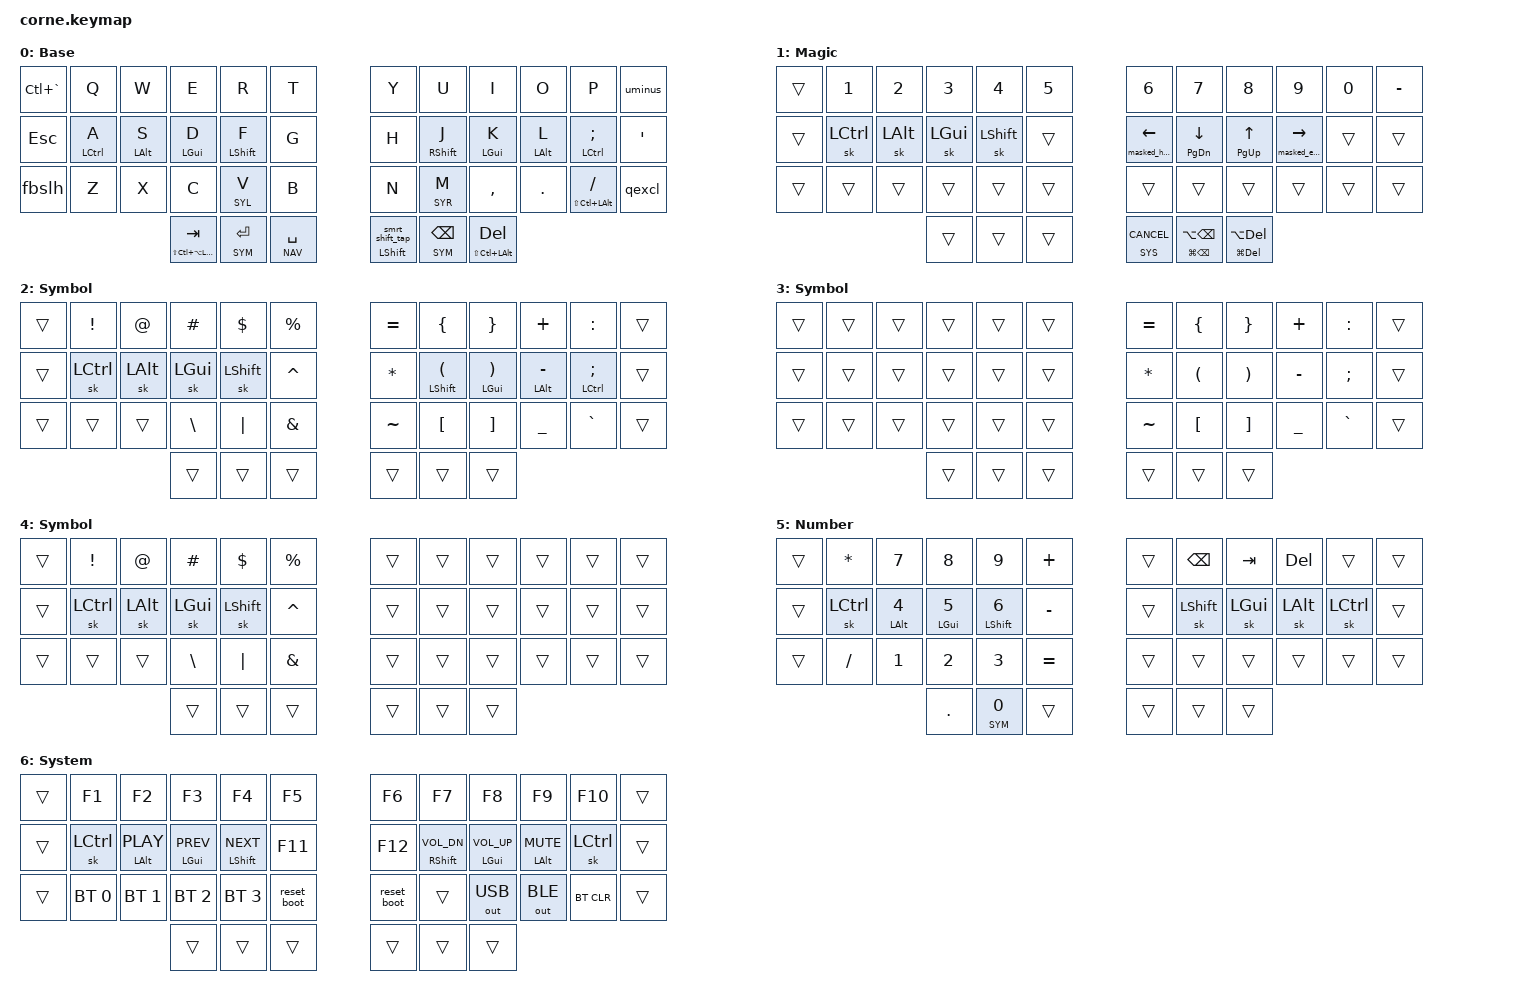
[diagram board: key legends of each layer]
#include <behaviors.dtsi>
#include <dt-bindings/zmk/keys.h>
#include <dt-bindings/zmk/bt.h>
#include <dt-bindings/zmk/outputs.h>
#include <dt-bindings/zmk/pointing.h>

#define DEF 0
#define NAV 1
#define SYM 2
#define SYL 3
#define SYR 4
#define NUM 5
#define SYS 6

#define XXX &none
#define ___ &trans

/* Global defaults */

#define QUICK_TAP_MS 175

&sk {
  release-after-ms = <900>;
  quick-release;
};

&sl { // Allow sticky mods to chord across sticky layers.
  ignore-modifiers;
};

&lt {
  flavor = "balanced";
  tapping-term-ms = <200>;
  quick-tap-ms = <QUICK_TAP_MS>;
};

/* Homerow mods */

#define KEYS_L 5 4 3 2 1 0 17 16 15 14 13 12 29 28 27 26 25 24
// #define KEYS_L 0 1 2 3 4 10 11 12 13 14 20 21 22 23 24
#define KEYS_R 6 7 8 9 10 11 18 19 20 21 22 23 30 31 32 33 34 35
// #define KEYS_R 5 6 7 8 9 15 16 17 18 19 25 26 27 28 29
#define THUMBS 36 37 38 39 40 41
// #define THUMBS 30 31 32 33

/* Nav cluster */

&mt { // Trigger tap-action on all interrupts.
  flavor = "tap-preferred";
  tapping-term-ms = <220>;
  quick-tap-ms = <220>;
  hold-trigger-key-positions = <0>;
};

// Home-row mods
#define HRLPAR  &hmr LSHFT LPAR
#define HRRPAR  &hmr LGUI  RPAR
#define HRMINUS &hmr LALT  MINUS
#define HRSEMI  &hmr LCTRL SEMI

#define HRPLAY &hml LALT  C_PLAY
#define HRPREV &hml LGUI  C_PREV
#define HRNEXT &hml LSHFT C_NEXT
#define HRVOLD &hml RSHFT C_VOL_DN
#define HRVOLU &hml LGUI  C_VOL_UP
#define HRMUTE &hml LALT  C_MUTE

#define HYP_TAB &mt LS(LC(LA(LGUI))) TAB
#define MEH_DEL &mt LS(LC(LALT))     DEL

#define MEH_SLH   &mt LS(LC(LALT)) FSLH
#define NAV_LEFT  &mt_home 0   LEFT     // Tap: left         | Long-tap: start of line.
#define NAV_DOWN  &mt PG_DN    DOWN     // Tap: down         | Long-tap: page down.
#define NAV_UP    &mt PG_UP    UP       // Tap: up           | Long-tap: page up.
#define NAV_RIGHT &mt_end 0    RIGHT    // Tap: right        | Long-tap: end   of line.
#define NAV_BSPC  &mt LG(BSPC) LA(BSPC) // Tap: bspc word    | Long-tap: bspc line.
#define NAV_DEL   &mt LG(DEL)  LA(DEL)  // Tap: del  word    | Long-tap: del  line.

/* Magic-shift & auto-layers */
#define SMRT_SHIFT &smrt_shift LSHFT 0

// Misc aliases. [TODO: clean up]
#define SYS_CANCEL &lt SYS K_CANCEL      // Cancel caps-word & auto-layers.
#define TERMNL     &kp LC(GRAVE)         // Open Terminal in VSCode
#define DSK_PREV   &kp LC(LEFT)          // Prev desktop.
#define DSK_APP    &kp LC(DOWN)          // Application windows.
#define DSK_ALL    &kp LC(UP)            // Mission Control.
#define DSK_NEXT   &kp LC(RIGHT)         // Next desktop.

/ {
  behaviors {
    hml: hml {
      compatible = "zmk,behavior-hold-tap";
      #binding-cells = <2>;
      bindings = <&kp>, <&kp>;
      flavor = "balanced";
      tapping-term-ms = <280>;
      quick-tap-ms = <QUICK_TAP_MS>;
      require-prior-idle-ms = <120>;
      hold-trigger-on-release;
      hold-trigger-key-positions = <KEYS_R THUMBS>;
    };
    hmr: hmr {
      compatible = "zmk,behavior-hold-tap";
      #binding-cells = <2>;
      bindings = <&kp>, <&kp>;
      flavor = "balanced";
      tapping-term-ms = <280>;
      quick-tap-ms = <QUICK_TAP_MS>;
      require-prior-idle-ms = <120>;
      hold-trigger-on-release;
      hold-trigger-key-positions = <KEYS_L THUMBS>;
    };
    bml: bml {
      compatible = "zmk,behavior-hold-tap";
      #binding-cells = <2>;
      bindings = <&mo>, <&kp>;
      flavor = "balanced";
      tapping-term-ms = <200>;
      quick-tap-ms = <QUICK_TAP_MS>;
      require-prior-idle-ms = <120>;
      hold-trigger-on-release;
      hold-trigger-key-positions = <KEYS_R THUMBS>;
    };
    bmr: bmr {
      compatible = "zmk,behavior-hold-tap";
      #binding-cells = <2>;
      bindings = <&mo>, <&kp>;
      flavor = "balanced";
      tapping-term-ms = <200>;
      quick-tap-ms = <QUICK_TAP_MS>;
      require-prior-idle-ms = <120>;
      hold-trigger-on-release;
      hold-trigger-key-positions = <KEYS_L THUMBS>;
    };

    mt_home: mt_home {
      compatible = "zmk,behavior-hold-tap";
      #binding-cells = <2>;
      bindings = <&masked_home>, <&kp>;
      flavor = "tap-preferred";
      tapping-term-ms = <220>;
      quick-tap-ms = <220>;
      hold-trigger-key-positions = <0>;
    };
    mt_end: mt_end {
      compatible = "zmk,behavior-hold-tap";
      #binding-cells = <2>;
      bindings = <&masked_end>, <&kp>;
      flavor = "tap-preferred";
      tapping-term-ms = <220>;
      quick-tap-ms = <220>;
      hold-trigger-key-positions = <0>;
    };

    // Tap: sticky-shift
    // Shift + tap/ double-tap: caps-word | Hold: shift.
    smrt_shift: smrt_shift {
      compatible = "zmk,behavior-hold-tap";
      #binding-cells = <2>;
      bindings = <&kp>, <&smrt_shift_tap>;
      flavor = "balanced";
      tapping-term-ms = <200>;
      quick-tap-ms = <QUICK_TAP_MS>;
    };
    smrt_shift_tap: smrt_shift_tap {
      compatible = "zmk,behavior-mod-morph";
      #binding-cells = <0>;
      bindings = <&sk LSHFT>, <&caps_word>;
      mods = <(MOD_LSFT)>;
    };

    // Mask GUI on left/right hold to avoid accidental jumps to start/end of doc.
    masked_home: masked_home {
      compatible = "zmk,behavior-mod-morph";
      #binding-cells = <0>;
      bindings = <&kp LG(LEFT)>, <&kp LG(LEFT)>;
      mods = <(MOD_LGUI)>;
    };
    masked_end: masked_end {
      compatible = "zmk,behavior-mod-morph";
      #binding-cells = <0>;
      bindings = <&kp LG(RIGHT)>, <&kp LG(RIGHT)>;
      mods = <(MOD_LGUI)>;
    };

    // Tap: comma | Shift + tap: semicolon | GUI + shift + tap: <.
    comma_morph: comma_morph {
      compatible = "zmk,behavior-mod-morph";
      #binding-cells = <0>;
      bindings = <&kp COMMA>, <&comma_inner_morph>;
      mods = <(MOD_LSFT | MOD_RSFT)>;
    };
    comma_inner_morph: comma_inner_morph {
      compatible = "zmk,behavior-mod-morph";
      #binding-cells = <0>;
      bindings = <&kp SEMICOLON>, <&kp LESS_THAN>;
      mods = <(MOD_LGUI | MOD_RGUI)>;
    };

    // Tap: dot | Shift + tap: colon | GUI + shift + tap: >.
    dot_morph: dot_morph {
      compatible = "zmk,behavior-mod-morph";
      #binding-cells = <0>;
      bindings = <&kp DOT>, <&dot_inner_morph>;
      mods = <(MOD_LSFT | MOD_RSFT)>;
    };
    dot_inner_morph: dot_inner_morph {
      compatible = "zmk,behavior-mod-morph";
      #binding-cells = <0>;
      bindings = <&kp COLON>, <&kp GREATER_THAN>;
      mods = <(MOD_LGUI | MOD_RGUI)>;
    };

    // Tap: qmark | Shift + tap: excl.
    qexcl: qexcl {
      compatible = "zmk,behavior-mod-morph";
      #binding-cells = <0>;
      bindings = <&kp EXCL>, <&kp QMARK>;
      mods = <(MOD_LSFT | MOD_RSFT)>;
    };

    // Tap: underscore | Shift + tap: minus.
    uminus: uminus {
      compatible = "zmk,behavior-mod-morph";
      #binding-cells = <0>;
      bindings = <&kp UNDER>, <&kp MINUS>;
      mods = <(MOD_LSFT | MOD_RSFT)>;
    };

    // Tap: forward slash | Shift + tap: back slash.
    fbslh: fbslh {
      compatible = "zmk,behavior-mod-morph";
      #binding-cells = <0>;
      bindings = <&kp FSLH>, <&kp BSLH>;
      mods = <(MOD_LSFT | MOD_RSFT)>;
    };

    reset_boot: reset_boot {
      compatible = "zmk,behavior-hold-tap";
      #binding-cells = <2>;
      bindings = <&sys_reset>, <&bootloader>;
      tapping-term-ms = <500>;
    };
  };
  combos {
    compatible = "zmk,combos";

    /* Horizontal combos - left hand */
    esc {
      bindings = <&kp ESC>;
      key-positions = <2 3>;
      layers = <DEF NAV SYM NUM>;
      timeout-ms = <22>;
      require-prior-idle-ms = <150>;
    };
    bspc {
      bindings = <&kp BSPC>;
      key-positions = <6 7>;
      layers = <DEF NAV SYM NUM>;
      timeout-ms = <22>;
      require-prior-idle-ms = <150>;
    };
    combo_cut {
      bindings = <&kp LG(X)>;
      key-positions = <26 28>;
      layers = <DEF NAV SYM NUM>;
      timeout-ms = <22>;
      require-prior-idle-ms = <150>;
    };
    combo_copy {
      bindings = <&kp LG(C)>;
      key-positions = <26 27>;
      layers = <DEF NAV SYM NUM>;
      timeout-ms = <22>;
      require-prior-idle-ms = <150>;
    };
    combo_paste {
      bindings = <&kp LG(V)>;
      key-positions = <27 28>;
      layers = <DEF NAV SYM NUM>;
      timeout-ms = <22>;
      require-prior-idle-ms = <150>;
    };

    /* Horizontal combos - right hand */
    scroll_up {
      bindings = <&msc SCRL_UP>;
      key-positions = <7 8 9>;
      layers = <DEF>;
      timeout-ms = <50>;
      require-prior-idle-ms = <150>;
    };
    scroll_down {
      bindings = <&msc SCRL_DOWN>;
      key-positions = <31 32 33>;
      layers = <DEF>;
      timeout-ms = <50>;
      require-prior-idle-ms = <150>;
    };

    caps_word {
      bindings = <&caps_word>;
      key-positions = <16 19>;
      layers = <DEF>;
      timeout-ms = <50>;
      require-prior-idle-ms = <150>;
    };
  };

  conditional_layers {
    compatible = "zmk,conditional-layers";
    tri_layer_sys {
      if-layers = <NUM SYM>;
      then-layer = <SYS>;
    };
  };
  
  keymap {
    compatible = "zmk,keymap";

    def {
      bindings = <
//╭─────────────┬─────────────┬─────────────┬─────────────┬─────────────┬─────────────╮ ╭─────────────┬─────────────┬─────────────┬─────────────┬─────────────┬─────────────╮
    TERMNL        &kp Q         &kp W         &kp E         &kp R         &kp T           &kp Y         &kp U         &kp I         &kp O         &kp P         &uminus
//├─────────────┼─────────────┼─────────────┼─────────────┼─────────────┼─────────────┤ ├─────────────┼─────────────┼─────────────┼─────────────┼─────────────┼─────────────┤
    &kp ESC       &hml LCTRL A  &hml LALT S   &hml LGUI D   &hml LSHFT F  &kp G           &kp H         &hmr RSHFT J  &hmr LGUI K   &hmr LALT L &hmr LCTRL SEMI &kp SQT
//├─────────────┼─────────────┼─────────────┼─────────────┼─────────────┼─────────────┤ ├─────────────┼─────────────┼─────────────┼─────────────┼─────────────┼─────────────┤
    &fbslh        &kp Z         &kp X         &kp C         &bml SYL V    &kp B           &kp N         &bmr SYR M    &kp COMMA     &kp DOT       MEH_SLH       &qexcl
//╰─────────────┼─────────────┴─────────────┼─────────────┼─────────────┼─────────────┤ ├─────────────┼─────────────┼─────────────┼─────────────┴─────────────┴─────────────╯
                                              HYP_TAB       &lt SYM RET   &lt NAV SPC     SMRT_SHIFT    &lt SYM BSPC  MEH_DEL
//                                          ╰─────────────┴─────────────┴─────────────╯ ╰─────────────┴─────────────┴─────────────╯
      >;
      label = "Base";
    };
    nav {
      bindings = <
//╭─────────────┬─────────────┬─────────────┬─────────────┬─────────────┬─────────────╮ ╭─────────────┬─────────────┬─────────────┬─────────────┬─────────────┬─────────────╮
    ___           &kp N1        &kp N2        &kp N3        &kp N4        &kp N5          &kp N6        &kp N7        &kp N8        &kp N9        &kp N0        &kp MINUS
//├─────────────┼─────────────┼─────────────┼─────────────┼─────────────┼─────────────┤ ├─────────────┼─────────────┼─────────────┼─────────────┼─────────────┼─────────────┤
    ___           &sk LCTRL     &sk LALT      &sk LGUI      &sk LSHFT     ___             NAV_LEFT      NAV_DOWN      NAV_UP        NAV_RIGHT     ___           ___
//├─────────────┼─────────────┼─────────────┼─────────────┼─────────────┼─────────────┤ ├─────────────┼─────────────┼─────────────┼─────────────┼─────────────┼─────────────┤
    ___           ___           ___           ___           ___           ___             ___           ___           ___           ___           ___           ___
//╰─────────────┼─────────────┴─────────────┼─────────────┼─────────────┼─────────────┤ ├─────────────┼─────────────┼─────────────┼─────────────┴─────────────┴─────────────╯
                                              ___           ___           ___             SYS_CANCEL    NAV_BSPC      NAV_DEL
//                                          ╰─────────────┴─────────────┴─────────────╯ ╰─────────────┴─────────────┴─────────────╯
      >;
      label = "Magic";
    };
    sym {
      bindings = <
//╭─────────────┬─────────────┬─────────────┬─────────────┬─────────────┬─────────────╮ ╭─────────────┬─────────────┬─────────────┬─────────────┬─────────────┬─────────────╮
    ___           &kp EXCL      &kp AT        &kp HASH      &kp DLLR      &kp PRCNT       &kp EQUAL     &kp LBRC      &kp RBRC      &kp PLUS      &kp COLON     ___
//├─────────────┼─────────────┼─────────────┼─────────────┼─────────────┼─────────────┤ ├─────────────┼─────────────┼─────────────┼─────────────┼─────────────┼─────────────┤
    ___           &sk LCTRL     &sk LALT      &sk LGUI      &sk LSHFT     &kp CARET       &kp STAR      HRLPAR        HRRPAR        HRMINUS       HRSEMI        ___
//├─────────────┼─────────────┼─────────────┼─────────────┼─────────────┼─────────────┤ ├─────────────┼─────────────┼─────────────┼─────────────┼─────────────┼─────────────┤
    ___           ___           ___           &kp BSLH      &kp PIPE      &kp AMPS        &kp TILDE     &kp LBKT      &kp RBKT      &kp UNDER     &kp GRAVE     ___
//╰─────────────┼─────────────┴─────────────┼─────────────┼─────────────┼─────────────┤ ├─────────────┼─────────────┼─────────────┼─────────────┴─────────────┴─────────────╯
                                              ___           ___           ___             ___           ___           ___
//                                          ╰─────────────┴─────────────┴─────────────╯ ╰─────────────┴─────────────┴─────────────╯
  >;
      label = "Symbol";
    };
    syl {
      bindings = <
//╭─────────────┬─────────────┬─────────────┬─────────────┬─────────────┬─────────────╮ ╭─────────────┬─────────────┬─────────────┬─────────────┬─────────────┬─────────────╮
    ___           ___           ___           ___           ___           ___             &kp EQUAL     &kp LBRC      &kp RBRC      &kp PLUS      &kp COLON     ___
//├─────────────┼─────────────┼─────────────┼─────────────┼─────────────┼─────────────┤ ├─────────────┼─────────────┼─────────────┼─────────────┼─────────────┼─────────────┤
    ___           ___           ___           ___           ___           ___             &kp STAR      &kp LPAR      &kp RPAR      &kp MINUS     &kp SEMI      ___
//├─────────────┼─────────────┼─────────────┼─────────────┼─────────────┼─────────────┤ ├─────────────┼─────────────┼─────────────┼─────────────┼─────────────┼─────────────┤
    ___           ___           ___           ___           ___           ___             &kp TILDE     &kp LBKT      &kp RBKT      &kp UNDER     &kp GRAVE     ___
//╰─────────────┼─────────────┴─────────────┼─────────────┼─────────────┼─────────────┤ ├─────────────┼─────────────┼─────────────┼─────────────┴─────────────┴─────────────╯
                                             ___           ___           ___             ___           ___           ___
//                                          ╰─────────────┴─────────────┴─────────────╯ ╰─────────────┴─────────────┴─────────────╯
  >;
      label = "Symbol";
    };
    syr {
      bindings = <
//╭─────────────┬─────────────┬─────────────┬─────────────┬─────────────┬─────────────╮ ╭─────────────┬─────────────┬─────────────┬─────────────┬─────────────┬─────────────╮
    ___           &kp EXCL      &kp AT        &kp HASH      &kp DLLR      &kp PRCNT       ___           ___           ___           ___           ___           ___
//├─────────────┼─────────────┼─────────────┼─────────────┼─────────────┼─────────────┤ ├─────────────┼─────────────┼─────────────┼─────────────┼─────────────┼─────────────┤
    ___           &sk LCTRL     &sk LALT      &sk LGUI      &sk LSHFT     &kp CARET       ___           ___           ___           ___           ___           ___
//├─────────────┼─────────────┼─────────────┼─────────────┼─────────────┼─────────────┤ ├─────────────┼─────────────┼─────────────┼─────────────┼─────────────┼─────────────┤
    ___           ___           ___           &kp BSLH      &kp PIPE      &kp AMPS        ___           ___           ___           ___           ___           ___
//╰─────────────┼─────────────┴─────────────┼─────────────┼─────────────┼─────────────┤ ├─────────────┼─────────────┼─────────────┼─────────────┴─────────────┴─────────────╯
                                              ___           ___           ___             ___           ___           ___
//                                          ╰─────────────┴─────────────┴─────────────╯ ╰─────────────┴─────────────┴─────────────╯
  >;
      label = "Symbol";
    };
    num {
      bindings = <
//╭─────────────┬─────────────┬─────────────┬─────────────┬─────────────┬─────────────╮ ╭─────────────┬─────────────┬─────────────┬─────────────┬─────────────┬─────────────╮
    ___           &kp STAR      &kp N7        &kp N8        &kp N9        &kp PLUS        ___           &kp BSPC      &kp TAB       &kp DEL       ___           ___
//├─────────────┼─────────────┼─────────────┼─────────────┼─────────────┼────────── ──┤ ├─────────────┼─────────────┼─────────────┼─────────────┼─────────────┼─────────────┤
    ___           &sk LCTRL     &hml LALT N4  &hml LGUI N5  &hml LSHFT N6 &kp MINUS       ___           &sk LSHFT     &sk LGUI      &sk LALT      &sk LCTRL     ___
//├─────────────┼─────────────┼─────────────┼─────────────┼─────────────┼────────── ──┤ ├─────────────┼─────────────┼─────────────┼─────────────┼─────────────┼─────────────┤
    ___           &kp FSLH      &kp N1        &kp N2        &kp N3        &kp EQUAL       ___           ___           ___           ___           ___           ___
//╰─────────────┼─────────────┴─────────────┼─────────────┼─────────────┼────────── ──┤ ├─────────────┼─────────────┼─────────────┼─────────────┴─────────────┴─────────────╯
                                              &kp DOT       &lt SYM N0    ___             ___           ___           ___
//                                          ╰─────────────┴─────────────┴─────────────╯ ╰─────────────┴─────────────┴─────────────╯
      >;
      label = "Number";
    };
    sys {
      bindings = <
      // &bt BT_SEL 0  &bt BT_SEL 1  &bt BT_SEL 2  &bt BT_SEL 3  &bt BT_SEL 4 &bt BT_CLR
//╭─────────────┬─────────────┬─────────────┬─────────────┬─────────────┬─────────────╮ ╭─────────────┬─────────────┬─────────────┬─────────────┬─────────────┬─────────────╮
    ___           &kp F1        &kp F2        &kp F3        &kp F4        &kp F5          &kp F6        &kp F7        &kp F8        &kp F9        &kp F10       ___
//├─────────────┼─────────────┼─────────────┼─────────────┼─────────────┼─────────────┤ ├─────────────┼─────────────┼─────────────┼─────────────┼─────────────┼─────────────┤
    ___           &sk LCTRL     HRPLAY        HRPREV        HRNEXT        &kp F11         &kp F12       HRVOLD        HRVOLU        HRMUTE        &sk LCTRL     ___
//├─────────────┼─────────────┼─────────────┼─────────────┼─────────────┼─────────────┤ ├─────────────┼─────────────┼─────────────┼─────────────┼─────────────┼─────────────┤
    ___           &bt BT_SEL 0  &bt BT_SEL 1  &bt BT_SEL 2  &bt BT_SEL 3  &reset_boot     &reset_boot   ___           &out OUT_USB  &out OUT_BLE  &bt BT_CLR    ___
//╰─────────────┼─────────────┴─────────────┼─────────────┼─────────────┼─────────────┤ ├─────────────┼─────────────┼─────────────┼─────────────┴─────────────┴─────────────╯
                                              ___           ___           ___             ___           ___           ___
//                                          ╰─────────────┴─────────────┴─────────────╯ ╰─────────────┴─────────────┴─────────────╯
      >;

      label = "System";
    };
  };
};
